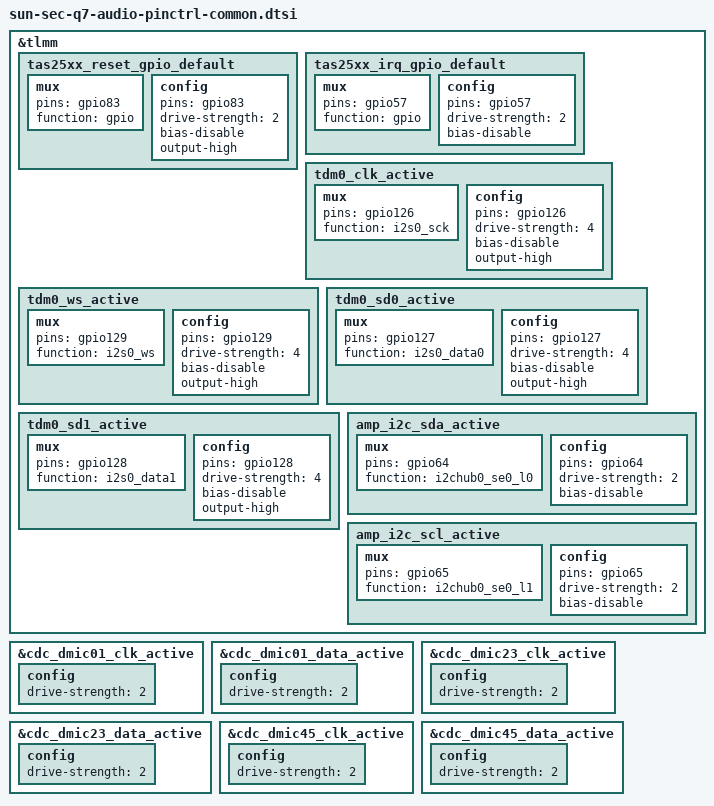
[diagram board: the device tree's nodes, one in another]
// SPDX-License-Identifier: BSD-3-Clause
/*
 * Copyright (c) 2023-2024 Qualcomm Innovation Center, Inc. All rights reserved.
 */

&tlmm {
	tas25xx_reset_gpio_default: tas25xx_reset_gpio_default {
		mux {
			pins = "gpio83";
			function = "gpio";
		};
		config {
			pins = "gpio83";
			drive-strength = <2>; /* 2 MA */
			bias-disable;           /* NO PULL */
			output-high;
		};
	};

	tas25xx_irq_gpio_default: tas25xx_irq_gpio_default {
		mux {
			pins = "gpio57";
			function = "gpio";
		};
		config {
			pins = "gpio57";
			drive-strength = <2>; /* 2 MA */
			bias-disable;           /* NO PULL */
		};
	};

	/delete-node/ tdm0_clk_active;
	tdm0_clk_active: tdm0_clk_active {
		mux {
			pins = "gpio126";
			function = "i2s0_sck";
		};

		config {
			pins = "gpio126";
			drive-strength = <4>;   /* 4 mA */
			bias-disable;           /* NO PULL */
			output-high;
		};
	};

	/delete-node/ tdm0_ws_active;
	tdm0_ws_active: tdm0_ws_active {
		mux {
			pins = "gpio129";
			function = "i2s0_ws";
		};

		config {
			pins = "gpio129";
			drive-strength = <4>;   /* 4 mA */
			bias-disable;           /* NO PULL */
			output-high;
		};
	};

	/delete-node/ tdm0_sd0_active;
	tdm0_sd0_active: tdm0_sd0_active {
		mux {
			pins = "gpio127";
			function = "i2s0_data0";
		};

		config {
			pins = "gpio127";
			drive-strength = <4>;   /* 4 mA */
			bias-disable;           /* NO PULL */
			output-high;
		};
	};

	/delete-node/ tdm0_sd1_active;
	tdm0_sd1_active: tdm0_sd1_active {
		mux {
			pins = "gpio128";
			function = "i2s0_data1";
		};

		config {
			pins = "gpio128";
			drive-strength = <4>;   /* 4 mA */
			bias-disable;           /* NO PULL */
			output-high;
		};
	};

	amp_i2c_sda_active: amp_i2c_sda_active{
		mux {
			pins = "gpio64";
			function = "i2chub0_se0_l0";
		};

		config {
			pins = "gpio64";
			drive-strength = <2>;
			bias-disable;
		};
	};

	amp_i2c_scl_active: amp_i2c_scl_active {
		mux {
			pins = "gpio65";
			function = "i2chub0_se0_l1";
		};

		config {
			pins = "gpio65";
			drive-strength = <2>;
			bias-disable;
		};
	};
};

&cdc_dmic01_clk_active {
	config {
		drive-strength = <2>;
	};
};

&cdc_dmic01_data_active {
	config {
		drive-strength = <2>;
	};
};

&cdc_dmic23_clk_active {
	config {
		drive-strength = <2>;
	};
};

&cdc_dmic23_data_active {
	config {
		drive-strength = <2>;
	};
};

&cdc_dmic45_clk_active {
	config {
		drive-strength = <2>;
	};
};

&cdc_dmic45_data_active {
	config {
		drive-strength = <2>;
	};
};
